# ipro6s register map
Vendor: intelpro; Series: IPRO6S
CPU: ipro6s, little endian
Registers are 32-bit, read-write, reset 0x0 unless marked. A register's access mark holds for its fields unless they carry their own. Offsets are from the block's base; [hi:lo] are bit positions; {n}, {i} and the like mark numbered series.

## RF (part 1 of 2)
Base 0x30001000
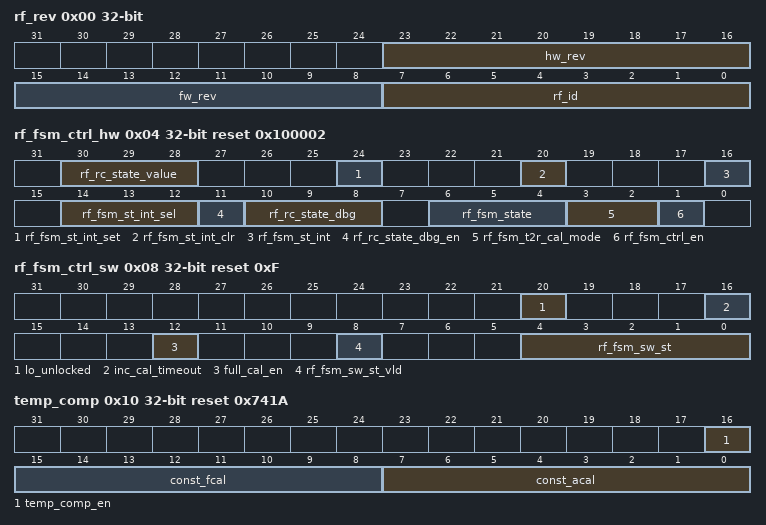
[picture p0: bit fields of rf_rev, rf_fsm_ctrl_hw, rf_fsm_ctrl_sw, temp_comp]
0x00 rf_rev reset not defined — Silicon revision
  [23:16] hw_rev ro — mark digital HW REV ID
  [15:8] fw_rev ro — mark firmware REV ID
  [7:0] rf_id ro — mark RF IP rev ID
0x04 rf_fsm_ctrl_hw reset 0x100002 (reset mask 0x1107F0E) — Digital Control
  [30:28] rf_rc_state_value ro — RC FSM state value
  [24] rf_fsm_st_int_set — RF FSM state interrupt set
  [20] rf_fsm_st_int_clr — RF FSM state interrupt clear
  [16] rf_fsm_st_int ro — RF FSM state interrupt value
  [14:12] rf_fsm_st_int_sel — WiFi FSM ST request, When selection, IRQ for certain ST will be reported 4'h0:FSM comes to RFrdy ST (after RF power up fullcal or power up incremental cal, next ST will be SB) 4'h1:FSM comes to SB ST (should be same as BB FSM status) 4'h2:FSM comes to RX ST (should be same as BB FSM status) 4'h3:FSM comes to TX ST (should be same as BB FSM status) 4'h4:FSM comes to Inccal_ros_afcal (for RF incremental calibration between TX to RX） 4'h5:FSM comes to inccal_tos_afcal (for RF incremental calibration between TX to RX，not RX-to-TX due to limited switching time）
  [11] rf_rc_state_dbg_en — 1:enable RC state from SW
  [10:8] rf_rc_state_dbg — SW RC state value
  [6:4] rf_fsm_state ro — RF FSM state value 0:ST_PD, 1:ST_SB, 2:ST_LO, 3:ST_RX, 4:ST_TX, 5:ST_T2RI, 6:ST_R2T, 7:ST_MS
  [3:2] rf_fsm_t2r_cal_mode — 2'd0:disable incremental calibration between TX/RX/ switching 2'd1:enable incremental ROS/A/F calibration between TX/RX switching 2'd2:(Reserved) enable incremental TOS calibration between TX/RX switching 2'd3:(Reserved) enable incremental ROS/TOS calibration between TX/RX switching
  [1] rf_fsm_ctrl_en — 1:enable HW RF FSM controller
0x08 rf_fsm_ctrl_sw reset 0xF (reset mask 0x1111F) — rfsm status reg
  [20] lo_unlocked ro — LO Unlock signal (hardware connect this signal to SoC interrupts)
  [16] inc_cal_timeout — indicate that inccal has timed out
  [12] full_cal_en — enable full calibration during 1) power up 2) unlocked 3) sw control
  [8] rf_fsm_sw_st_vld — Calibration FSM and function FSM Status Valid Signal, this valid=1 means rf_fsm_st is right available
  [4:0] rf_fsm_sw_st — Calibration FSM and function FSM Status Signal: 0~7: is hardware state; 8~31: is software state
0x0C rfctrl_hw_en — Control logic switch
  [31:0] rf_reserved3
0x10 temp_comp reset 0x741A
  [16] temp_comp_en — 1'b1: enable temperature compensation for LO amplitude and frequency inc_cal
  [15:8] const_fcal — fcal temperature compensaton constant
  [7:0] const_acal — acal temperature compensaton constant
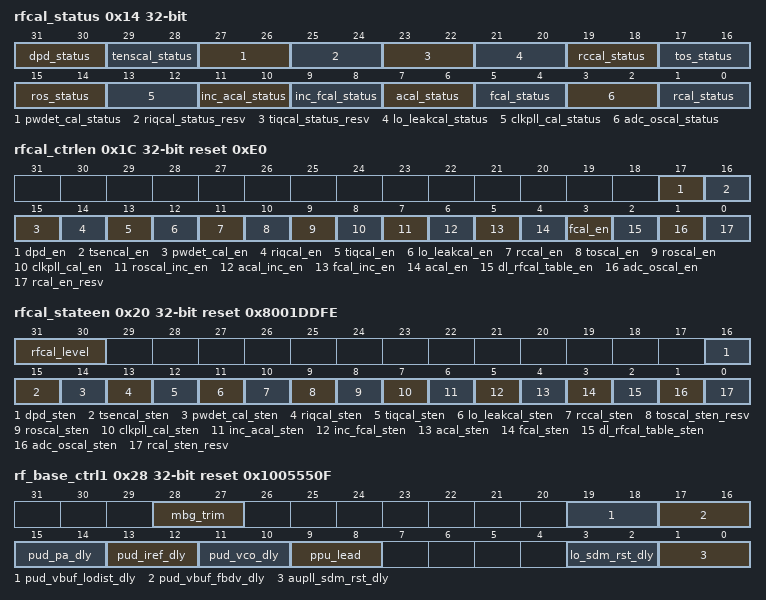
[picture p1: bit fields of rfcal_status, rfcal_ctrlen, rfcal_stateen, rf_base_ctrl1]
0x14 rfcal_status
  [31:30] dpd_status — dpd status : 0: not started, 1: on-going, 2: fail, 3:pass
  [29:28] tenscal_status — tenscal (Tref record) status : 0: not started, 1: on-going, 2: fail, 3:pass
  [27:26] pwdet_cal_status — pwdet_cal status : 0: not started, 1: on-going, 2: fail, 3:pass
  [25:24] riqcal_status_resv — 0: not started, 1: on-going, 2: fail, 3:pass
  [23:22] tiqcal_status_resv — 0: not started, 1: on-going, 2: fail, 3:pass
  [21:20] lo_leakcal_status — 0: not started, 1: on-going, 2: fail, 3:pass
  [19:18] rccal_status — RC calibration status: 0: not started, 1: on-going, 2: fail, 3:pass
  [17:16] tos_status — tos status : 0: not started, 1: on-going, 2: fail, 3:pass
  [15:14] ros_status — ros status : 0: not started, 1: on-going, 2: fail, 3:pass
  [13:12] clkpll_cal_status — clkpll cal status: 0: not started, 1: on-going, 2: fail, 3:pass
  [11:10] inc_acal_status — incremental acal status: 0: not started, 1: on-going, 2: fail, 3:pass
  [9:8] inc_fcal_status — incremental fcal status: 0: not started, 1: on-going, 2: fail, 3:pass
  [7:6] acal_status — acal status: 0: not started, 1: on-going, 2: fail, 3:pass
  [5:4] fcal_status — fcal status: 0: not started, 1: on-going, 2: fail, 3:pass
  [3:2] adc_oscal_status — GPADC and SARADC os cal status: 0: not started, 1: on-going, 2: fail, 3:pass
  [1:0] rcal_status — rcal status : 0: not started, 1: on-going, 2: fail, 3:pass
0x18 rfcal_status2
  [1:0] dl_rfcal_table_status — no calibration, just download RFCAL table status : 0: not started, 1: on-going, 2: fail, 3:pass
0x1C rfcal_ctrlen reset 0xE0 — Calibration mode register
  [17] dpd_en — 1'b1: enable dpd mode
  [16] tsencal_en — reserved
  [15] pwdet_cal_en — 1'b1: enable power det calibration
  [14] riqcal_en — BB IP has RX IQ already
  [13] tiqcal_en — 1'b1: enable calibration
  [12] lo_leakcal_en — 1'b1: enable calibration
  [11] rccal_en — 1'b1: enable RCCAL
  [10] toscal_en — 1'b1: enable TOSCAL
  [9] roscal_en — 1'b1: enable ROSCAL
  [8] clkpll_cal_en — 1'b1: enable clkpll cal
  [7] roscal_inc_en — 1'b1: enable increamental roscal
  [6] acal_inc_en — 1'b1: enable increamental ACAL
  [5] fcal_inc_en — 1'b1: enable increamental FCAL
  [4] acal_en — 1'b1: enable ACAL
  [3] fcal_en — 1’b1:enable FCAL when pu_cal_fcal=1
  [2] dl_rfcal_table_en — 1'b1: enable download RFCAL table, no calibrations
  [1] adc_oscal_en — 1'b1: enable GPADC and SARADC OS calibration
  [0] rcal_en_resv — no RCAL in this version
0x20 rfcal_stateen reset 0x8001DDFE — rf calibration state enabl in full cal list
  [31:30] rfcal_level — rf calbiration level: 1:fast calibration, download previous table; 2: full cal without ATE onetime cal; 3: full cal with ATE onetime cal; during ATE, change the value from 2 to 3;
  [16] dpd_sten — 1'b1: enable dpd state in calibration list
  [15] tsencal_sten — 1'b1: enable temperature sensor calibration state in calibration list
  [14] pwdet_cal_sten — 1'b1: enable power det calibration state in calibration list
  [13] riqcal_sten — Because CEVA IP has RX IQ already, reserved
  [12] tiqcal_sten — 1'b1: enable calibration state in calibration list
  [11] lo_leakcal_sten — 1'b1: enable calibration state in calibration list
  [10] rccal_sten — 1'b1: enable RCCAL state in calibration list
  [9] toscal_sten_resv — 1'b1: enable tOSCAL state in calibration list
  [8] roscal_sten — 1'b1: enable ROSCAL state in calibration list
  [7] clkpll_cal_sten — 1'b1: enable clkpll calibration state in calibration list
  [6] inc_acal_sten — 1'b1: enable increamental ACAL state in calibration list
  [5] inc_fcal_sten — 1'b1: enable increamental FCAL state in calibration list
  [4] acal_sten — 1'b1: enable ACAL state in calibration list
  [3] fcal_sten — 1’b1:enable FCAL state in calibration list
  [2] dl_rfcal_table_sten — 1'b1: enable download RFCAL table state, no other calibrations
  [1] adc_oscal_sten — 1'b1: enable GPADC and SARADC OS calibration
  [0] rcal_sten_resv — 1'b1: enable RCAL state in calibration list
0x24 saradc_resv reset not defined — SARADC Control Registers
0x28 rf_base_ctrl1 reset 0x1005550F — ZRF Control register 0
  [28:27] mbg_trim — (added)bandgap curve trimming
  [19:18] pud_vbuf_lodist_dly — PUD_VBUF_LODIST delay, PUD delay to bypass resistor to charge the capacitor fast 2'b00: 2 us 2'b01: 4 us 2'b10: 6 us 2'b11: 8 us
  [17:16] pud_vbuf_fbdv_dly — PUD_VBUF_FBDV delay, PUD delay to bypass resistor to charge the capacitor fast 2'b00: 2 us 2'b01: 4 us 2'b10: 6 us 2'b11: 8 us
  [15:14] pud_pa_dly — PUD_PA delay, to bypass R in RC filtering for fast settling at REF_CLK rate 2'b00: 1.5 us 2'b01: 3 us 2'b10: 4.5 us 2'b11: 6 us
  [13:12] pud_iref_dly — PUD_IREF delay, to bypass R in RC filtering for fast settling at REF_CLK rate 2'b00: 2 us 2'b01: 4 us 2'b10: 6 us 2'b11: 8 us
  [11:10] pud_vco_dly — PUD_VCO delay, PUD delay to bypass resistor to charge the capacitor fast 2'b00: 2 us 2'b01: 4 us 2'b10: 6 us 2'b11: 8 us
  [9:8] ppu_lead — pre PD signal lead to PU signal, to define lead time between PPU_xxxx and PU_xxx, ex: PPU_VCO and PU_VCO 2'b00: 0.2 us 2'b01: 0.4 us 2'b10: 0.6 us 2'b11: 0.8 us
  [3:2] lo_sdm_rst_dly — programable ref_clk delay, from falling edge of ana_sdm_rst to falling edge of ctrl_txdp_clr
  [1:0] aupll_sdm_rst_dly — programable ref_clk delay, from falling edge of ana_sdm_rst to falling edge of ctrl_txdp_clr
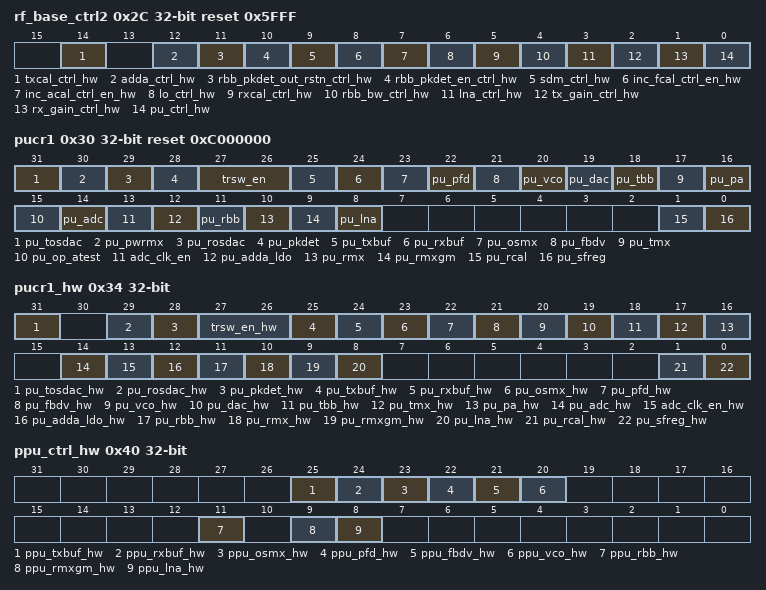
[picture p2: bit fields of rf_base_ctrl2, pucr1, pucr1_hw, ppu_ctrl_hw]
0x2C rf_base_ctrl2 reset 0x5FFF — ZRF Control register 0
  [14] txcal_ctrl_hw — 1: tx calibration related control bits are controlled by dsp 0: tx calibration related control bits are controlled by this register map Related Signals: tbb_tosdac_i/tbb_tosdac_q/tx_iqc_gain/tx_iqc_phase
  [12] adda_ctrl_hw — 1: adda_lo_dvddsel is controlled by dsp 0: adda_lo_dvddse is controlled by this register map
  [11] rbb_pkdet_out_rstn_ctrl_hw — 1: rbb_pkdet_out_rstn is controlled by dsp 0: rbb_pkdet_out_rstn is controlled by this register map
  [10] rbb_pkdet_en_ctrl_hw — 1: rbb_pkdet_en is controlled by dsp 0: rbb_pkdet_en is controlled by this register map
  [9] sdm_ctrl_hw — 1: lo sdm dither related control bits are controlled by dsp 0: lo sdm dither related control bits are controlled by this register map Related Signals: lo_sdm_bypass
  [8] inc_fcal_ctrl_en_hw — 1: fcal_inc_en is controlled by dsp 0: fcal_inc_en are controlled by this register map
  [7] inc_acal_ctrl_en_hw — 1: acal_inc_en is controlled by dsp 0: acal_inc_en is controlled by this register map
  [6] lo_ctrl_hw — 1: lo bandwidth/idac/fcw control bits are controlled by hardware logic input 0: lo bandwidth/idac/fcw control bits are controlled by this register map Related Singals: fsm_lo_sdm, fsm_lo_sdm_rstb, fsm_lo_fbdv_rst, fsm_lo_pfd_rst_csd, lo_fbdv_halfstep_en, lo_cp_sel, lo_lf_cz, lo_lf_rz, lo_lf_r4
  [5] rxcal_ctrl_hw — 1: rx calibration related control bits are controlled by dsp 0: rx calibration related control bits are controlled by this register map value Related Signals: rosdac_i_hw/rosdac_q_hw
  [4] rbb_bw_ctrl_hw — 1: rbb_bt_mode is controlled by dsp 0: rbb_bt_mode is controlled by this register map value
  [3] lna_ctrl_hw — 1: lna bm and csw are controlled by hardware logic input 0: lna bm and csw are controlled by this register map
  [2] tx_gain_ctrl_hw — 1: TX gain control are controlled by hardware logic input, ex gx_xxx_hw 0: TX gain control bits are controlled by this register map gc_xxx value
  [1] rx_gain_ctrl_hw — 1: RX gain control are controlled by hardware logic input, ex gx_xxx_hw 0: RX gain control bits are controlled by this register map gc_xxx value
  [0] pu_ctrl_hw — 1: pu control bits are controlled by hardware logic input, ex: pu_xxx_hw 0: pu regs are controlled by this register map pu_xxx value
0x30 pucr1 reset 0xC000000
  [31] pu_tosdac — 1'b1: power up TOSDAC
  [30] pu_pwrmx — 1'b1: power up power mx
  [29] pu_rosdac — 1'b1: power up TIA ROSDAC
  [28] pu_pkdet — 1'b1: power up TIA PKDET
  [27:26] trsw_en — 2'b3: TX mode 2'b0: RX mode
  [25] pu_txbuf — 1'b1: power up TX BUF
  [24] pu_rxbuf — 1'b1: power up RX BUF
  [23] pu_osmx — 1'b1: power up OSMX
  [22] pu_pfd — 1'b1: power up Charge Pump/PFD
  [21] pu_fbdv — 1'b1: power up FBDV
  [20] pu_vco — 1'b1: power up DCO
  [19] pu_dac — 1'b1: power up DAC
  [18] pu_tbb — 1'b1: power up TBB
  [17] pu_tmx — 1'b1: power up TMX
  [16] pu_pa — 1'b1: power up PA
  [15] pu_op_atest — 1'b1: power up atest buffer
  [14] pu_adc — 1'b1: power up ADC
  [13] adc_clk_en — 1'b1: Clock enable
  [12] pu_adda_ldo — 1'b1: power up ADDA LDO
  [11] pu_rbb — 1'b1: power up RBB
  [10] pu_rmx — 1'b1: power up RMX
  [9] pu_rmxgm — 1'b1: power up RMXGM
  [8] pu_lna — 1'b1: power up LNA
  [1] pu_rcal — 1'b1: power up rcal block
  [0] pu_sfreg — 1'b1: power up source follow regular
0x34 pucr1_hw reset not defined — read only from hardware logic
  [31] pu_tosdac_hw ro — 1'b1: power up TOSDAC
  [29] pu_rosdac_hw ro — 1'b1: power up TIA ROSDAC
  [28] pu_pkdet_hw ro — 1'b1: power up TIA PKDET
  [27:26] trsw_en_hw ro — 2'b3: TX mode 2'b0: RX mode
  [25] pu_txbuf_hw ro — 1'b1: power up TX BUF
  [24] pu_rxbuf_hw ro — 1'b1: power up RX BUF
  [23] pu_osmx_hw ro — 1'b1: power up OSMX
  [22] pu_pfd_hw ro — 1'b1: power up Charge Pump/PFD
  [21] pu_fbdv_hw ro — 1'b1: power up FBDV
  [20] pu_vco_hw ro — 1'b1: power up DCO
  [19] pu_dac_hw ro — 1'b1: power up DAC
  [18] pu_tbb_hw ro — 1'b1: power up TBB
  [17] pu_tmx_hw ro — 1'b1: power up TMX
  [16] pu_pa_hw ro — 1'b1: power up PA
  [14] pu_adc_hw ro — 1'b1: power up ADC
  [13] adc_clk_en_hw ro — 1'b1: Clock enable
  [12] pu_adda_ldo_hw ro — 1'b1: power up ADDA LDO
  [11] pu_rbb_hw ro — 1'b1: power up RBB
  [10] pu_rmx_hw ro — 1'b1: power up RMX
  [9] pu_rmxgm_hw ro — 1'b1: power up RMXGM
  [8] pu_lna_hw ro — 1'b1: power up LNA
  [1] pu_rcal_hw ro — 1'b1: power up rcal block
  [0] pu_sfreg_hw ro — 1'b1: power up source follow regular
0x38 pucr2 reset not defined
0x3C pucr2_hw reset not defined
0x40 ppu_ctrl_hw reset not defined
  [25] ppu_txbuf_hw ro — ppu_lead time ahead of pu_txbuf or pu_txbuf_hw
  [24] ppu_rxbuf_hw ro — ppu_lead time ahead of pu_rxbuf or pu_rxbuf_hw
  [23] ppu_osmx_hw ro — ppu_lead time ahead of pu_osmx or pu_osmx_hw
  [22] ppu_pfd_hw ro — ppu_lead time ahead of pu_pfd or pu_pfd_hw
  [21] ppu_fbdv_hw ro — ppu_lead time ahead of pu_fbdv or pu_fbdv_hw
  [20] ppu_vco_hw ro — ppu_lead time ahead of pu_vco or pu_vco_hw
  [11] ppu_rbb_hw ro — pu_rbb_hw
  [9] ppu_rmxgm_hw ro — ppu_lead time ahead of pu_rmxgm or pu_rmxgm_hw
  [8] ppu_lna_hw ro — pu_lna_hw
0x44 pud_ctrl_hw reset not defined
  [20] pud_vco_hw ro — pud_vco_dly time after of pu_vco or pu_vco_hw
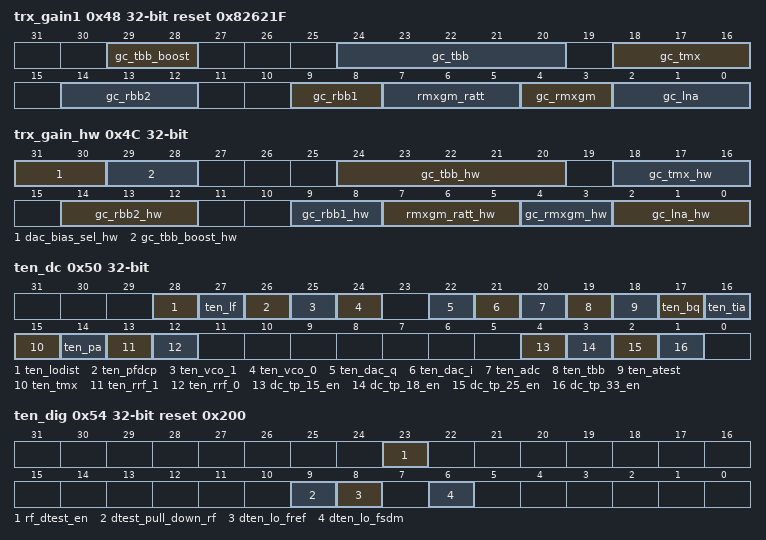
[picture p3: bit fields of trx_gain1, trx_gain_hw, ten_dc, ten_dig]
0x48 trx_gain1 reset 0x82621F — gain control1
  [29:28] gc_tbb_boost — 0: 0x, 1: 4x, 2: 4x, 3: 8x
  [24:20] gc_tbb — 0: 0.5x, 1: 2x … 15: 8x … 31: 16x
  [18:16] gc_tmx — tmx gain code
  [14:12] gc_rbb2 — rbb_gain2: 3'b000:-6dB, 3'b001:-4dB, 3'b010:-2dB, 3'b011:0dB, 3'b100:2dB, 3'b101:4dB, 3'b110:6dB, 3'b111:8dB
  [9:8] gc_rbb1 — rbb_gain1:1'b00:-6dB, 1'b01:0dB, 1'b10:6dB, 1'b11:rsvd
  [7:5] rmxgm_ratt — 0: 0dB, 1:-6dB, 2:-9dB, 3:-12dB
  [4:3] gc_rmxgm — rmxgm_gc: 2'h3:highest gain, 2'h1:highest gain -6dB, and 10M mode highest gain, 2'h0: -12dB
  [2:0] gc_lna — lna_gain: 3'b7:57dB, 3'b6:51dB, 3'b5:45dB, 3'b4:39dB, 3'b3:33dB, 3'b2:27dB, 3'b1:21dB, 3'b0:15dB
0x4C trx_gain_hw reset not defined — trx gain hardware readback
  [31:30] dac_bias_sel_hw ro — dac_bias_sel readback
  [29:28] gc_tbb_boost_hw ro — gc_tbb_boost readback
  [24:20] gc_tbb_hw ro — gc_tbb readback
  [18:16] gc_tmx_hw ro — gc_tmx readback
  [14:12] gc_rbb2_hw ro — gc_rbb2 readback
  [9:8] gc_rbb1_hw ro — gc_rbb1 readback
  [7:5] rmxgm_ratt_hw ro — rmgm_ratt_readback
  [4:3] gc_rmxgm_hw ro — gc_rmxgm readback
  [2:0] gc_lna_hw ro — gc_lna readback
0x50 ten_dc — dc test register
  [28] ten_lodist — 1'b1: enable this block dc test
  [27] ten_lf — 1'b1: enable this block dc test
  [26] ten_pfdcp — 1'b1: enable this block dc test
  [25] ten_vco_1 — 1'b1: enable this block dc test
  [24] ten_vco_0 — 1'b1: enable this block dc test
  [22] ten_dac_q — 1'b1: enable this block dc test
  [21] ten_dac_i — 1'b1: enable this block dc test
  [20] ten_adc — 1'b1: enable this block dc test
  [19] ten_tbb — 1'b1: enable this block dc test
  [18] ten_atest — 1'b1: enable this block dc test
  [17] ten_bq — 1'b1: enable this block dc test
  [16] ten_tia — 1'b1: enable this block dc test
  [15] ten_tmx — 1'b1: enable this block dc test
  [14] ten_pa — 1'b1: enable this block dc test
  [13] ten_rrf_1 — 1'b1: enable this block dc test
  [12] ten_rrf_0 — 1'b1: enable this block dc test
  [4] dc_tp_15_en — 1'b1: enable dc_15 test
  [3] dc_tp_18_en — 1'b1: enable dc_18 test
  [2] dc_tp_25_en — 1'b1: enable dc_25 test
  [1] dc_tp_33_en — 1'b1: enable dc_33 test
0x54 ten_dig reset 0x200 — digital test register
  [23] rf_dtest_en — 1: enable RF digital test to pad switch
  [9] dtest_pull_down_rf — 1'b1: enable this blcok dtest
  [8] dten_lo_fref — 1'b1: enable this blcok dtest
  [6] dten_lo_fsdm — 1'b1: enable this blcok dtest
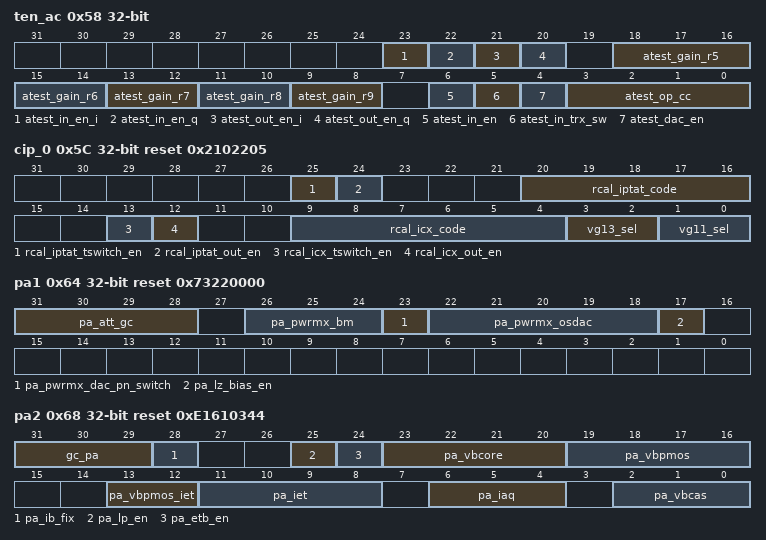
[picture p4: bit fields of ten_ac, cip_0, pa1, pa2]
0x58 ten_ac — ac test register
  [23] atest_in_en_i — 1'b1: enable atest input switch for I channel
  [22] atest_in_en_q — 1'b1: enable atest input switch for Q channel
  [21] atest_out_en_i — 1'b1: enable atest output switch for I channel
  [20] atest_out_en_q — 1'b1: enable atest output switch for Q channel
  [18:16] atest_gain_r5
  [27-2n:26-2n] atest_gain_r{n} (n=6..9)
  [6] atest_in_en
  [5] atest_in_trx_sw
  [4] atest_dac_en
  [3:0] atest_op_cc
0x5C cip_0 reset 0x2102205 — RX normal bias mode registers
  [25] rcal_iptat_tswitch_en
  [24] rcal_iptat_out_en
  [20:16] rcal_iptat_code
  [13] rcal_icx_tswitch_en
  [12] rcal_icx_out_en
  [9:4] rcal_icx_code
  [3:2] vg13_sel — 0: 1.25V, 1: 1.3V, 2: 1.35V, 3: 1.4V
  [1:0] vg11_sel — vg13-vg11 delta voltage. 0: 0.15V, 1: 0.2V, 2: 0.25V, 3: 0.3V
0x60 pa0 reset 0x1
  [1:0] pa_pwrmx_osdac_bm
0x64 pa1 reset 0x73220000
  [31:28] pa_att_gc — pa output atentuator gain code
  [26:24] pa_pwrmx_bm — pa power mixer bias mode
  [23] pa_pwrmx_dac_pn_switch — pa power mixer offset dac output p/n switch
  [22:18] pa_pwrmx_osdac — pa power mixer offset dac code
  [17] pa_lz_bias_en
0x68 pa2 reset 0xE1610344 — RX normal bias mode registers
  [31:29] gc_pa, [28] pa_ib_fix, [25] pa_lp_en, [24] pa_etb_en, [23:20] pa_vbcore, [19:16] pa_vbpmos, [13:12] pa_vbpmos_iet, [11:8] pa_iet, [6:4] pa_iaq, [2:0] pa_vbcas
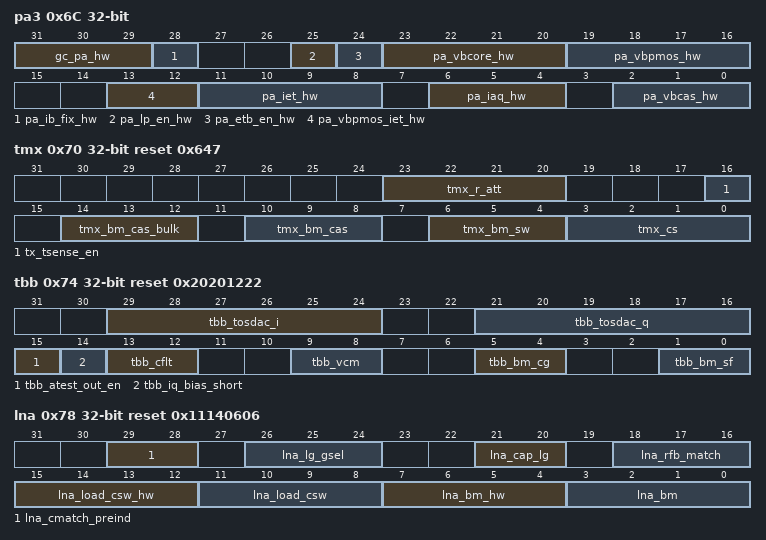
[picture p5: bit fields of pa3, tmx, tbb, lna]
0x6C pa3 reset not defined
  [31:29] gc_pa_hw ro, [28] pa_ib_fix_hw ro, [25] pa_lp_en_hw ro, [24] pa_etb_en_hw ro, [23:20] pa_vbcore_hw ro, [19:16] pa_vbpmos_hw ro, [13:12] pa_vbpmos_iet_hw ro, [11:8] pa_iet_hw ro, [6:4] pa_iaq_hw ro, [2:0] pa_vbcas_hw ro
0x70 tmx reset 0x647
  [23:20] tmx_r_att
  [16] tx_tsense_en — tx temperature sensor enable
  [14:12] tmx_bm_cas_bulk
  [10:8] tmx_bm_cas
  [6:4] tmx_bm_sw
  [3:0] tmx_cs — tmx xfmr output stage cap tuning contrl
0x74 tbb reset 0x20201222
  [29:24] tbb_tosdac_i
  [21:16] tbb_tosdac_q
  [15] tbb_atest_out_en
  [14] tbb_iq_bias_short
  [13:12] tbb_cflt
  [9:8] tbb_vcm — 0: 500mV, 1: 550mV, 2: 600mV, 3: 650mV
  [5:4] tbb_bm_cg — 0: 0.1mA, 1: 0.15mA, 2: 0.2mA, 3: 0.25mA
  [1:0] tbb_bm_sf — 0: 0.2mA, 1: 0.3mA, 3: 0.4mA, 4: 0.5mA
0x78 lna reset 0x11140606 (reset mask 0x37370F0F)
  [29:28] lna_cmatch_preind
  [26:24] lna_lg_gsel — lna LG gain control by tuning current mirror size
  [21:20] lna_cap_lg — lna LG input tuning cap control
  [18:16] lna_rfb_match — lna input feedback resistor control
  [15:12] lna_load_csw_hw ro — lna_load_csw hardware read back
  [11:8] lna_load_csw — lna loading cap tuning control
  [7:4] lna_bm_hw ro — lna_bm hardware read back
  [3:0] lna_bm — lna bias current control, default: hg=6, lg=4
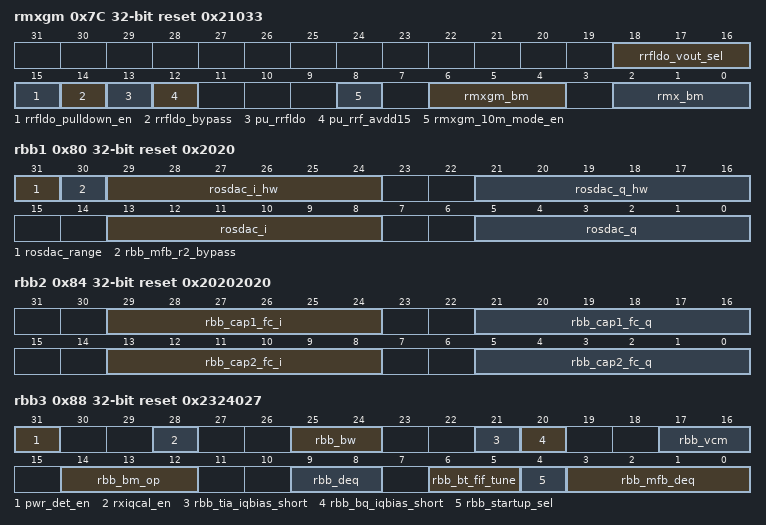
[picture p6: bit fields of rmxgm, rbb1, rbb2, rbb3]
0x7C rmxgm reset 0x21033
  [18:16] rrfldo_vout_sel — 0:1.62V, 1:1.72V, 2:1.82V, 3:1.92V, 4:2.02V
  [15] rrfldo_pulldown_en — 1'h1: enable rrfldo pulldown
  [14] rrfldo_bypass — 1'h1: bypass mode
  [13] pu_rrfldo — 1'h1: rrfldo pu ctrl by pu_adda_ldo from fsm, 1'h0: rrfldo always off
  [12] pu_rrf_avdd15 — 1'h1: LNA use supply from ldo15rf
  [8] rmxgm_10m_mode_en — 1'h0: wifi mode, 1'h1: 10m mode
  [6:4] rmxgm_bm — rmxgm bias current control, default = 3
  [2:0] rmx_bm — rmx bias voltage control, default = 3 , 0.85V
0x80 rbb1 reset 0x2020 (reset mask 0xC0003F3F)
  [31] rosdac_range
  [30] rbb_mfb_r2_bypass — 0: 4th order LPF, 1: 3rd order LPF
  [29:24] rosdac_i_hw ro
  [21:16] rosdac_q_hw ro
  [13:8] rosdac_i
  [5:0] rosdac_q
0x84 rbb2 reset 0x20202020
  [29:24] rbb_cap1_fc_i — capbank tuning for TIA I channel
  [21:16] rbb_cap1_fc_q — capbank tuning for TIA Q channel
  [13:8] rbb_cap2_fc_i — capbank tuning for BQ I channel
  [5:0] rbb_cap2_fc_q — capbank tuning for BQ Q channel
0x88 rbb3 reset 0x2324027
  [31] pwr_det_en — power detect related signal path enable control
  [28] rxiqcal_en — rxiqcal related signal path enable control
  [25:24] rbb_bw — 0: n/a, 1: 5M mode, 2:10M mode, 3: 20M mode
  [21] rbb_tia_iqbias_short
  [20] rbb_bq_iqbias_short
  [17:16] rbb_vcm — 0: 610mV, 1: 650mV, 2: 690mV, 3:720mV
  [14:12] rbb_bm_op — 0: 50%, 1: 62.5%, 2: 75%, 3: 87.5%, 4: 100%, 5: 112.5%, 6: 125%, 7: 137.5%
  [9:8] rbb_deq
  [6:5] rbb_bt_fif_tune
  [4] rbb_startup_sel — 0: track corner, 1: track vcm
  [3:0] rbb_mfb_deq — 7: r2_mfb=200Ohm
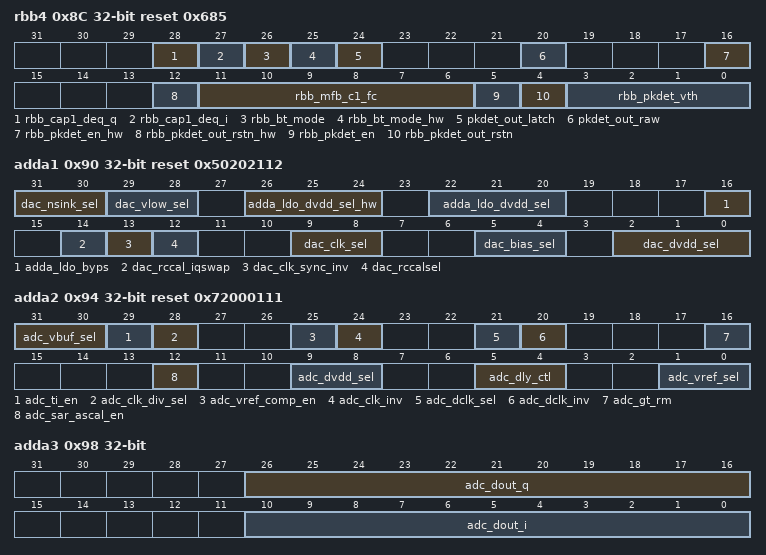
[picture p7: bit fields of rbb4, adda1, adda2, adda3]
0x8C rbb4 reset 0x685 (reset mask 0x1C000FFF)
  [28] rbb_cap1_deq_q
  [27] rbb_cap1_deq_i
  [26] rbb_bt_mode
  [25] rbb_bt_mode_hw ro — controlled by rbb_bw_ctrl_hw
  [24] pkdet_out_latch ro
  [20] pkdet_out_raw ro
  [16] rbb_pkdet_en_hw ro
  [12] rbb_pkdet_out_rstn_hw ro
  [11:6] rbb_mfb_c1_fc — 0x1a:C1_mfb=10pF
  [5] rbb_pkdet_en
  [4] rbb_pkdet_out_rstn
  [3:0] rbb_pkdet_vth
0x90 adda1 reset 0x50202112 (reset mask 0xF0717337)
  [31:30] dac_nsink_sel — 2'b00: 0 bias offset 2'b01: 10uA bias offset 2'b10: 20uA bias offset 2'b11: 30uA bias offset
  [29:28] dac_vlow_sel
  [26:24] adda_ldo_dvdd_sel_hw ro
  [22:20] adda_ldo_dvdd_sel — 3'h0: dvdd20=1.80V 3'h1: dvdd20=1.90V 3'h2: dvdd20=2.0V (default for ADC) 3'h3: dvdd20=2.05V 3'h4: dvdd20=2.1V (default for DAC) 3'h5: dvdd20=2.15V 3'h6: dvdd20=2.2V 3'h7: dvdd20=2.25V
  [16] adda_ldo_byps — 1'b0: ldo not bypass 1'b1: ldo bypass
  [14] dac_rccal_iqswap — 1'b0: Normal 1'b1: rccal output IQ swap
  [13] dac_clk_sync_inv — 1'b0: clock falling edge to sync input data 1'b1: clock rising edge to sync input data
  [12] dac_rccalsel — 1'b0: Normal 1'b1: output to dodpin
  [9:8] dac_clk_sel — 2'b00: 80 clock duty cycle for power up fast settling 2'b01: 160 clock duty cycle for power up fast settling 2'b10: 320 clock duty cycle for power up fast settling 2'b11: 640 clock duty cycle for power up fast settling
  [5:4] dac_bias_sel — 2'b00: LSB=0.375uA 2'b01: LSB=0.5uA 2'b10: LSB=0.625uA 2'b11: LSB=0.75uA
  [2:0] dac_dvdd_sel — 3'h1: dvdd11=1.15V 3'h2: dvdd11=1.20V 3'h3: dvdd11=1.25V 3'h4: dvdd11=1.3V 3'h5: dvdd11=1.35V 3'h6: dvdd11=1.4V 3'h7: dvdd11=1.45V
0x94 adda2 reset 0x72000111
  [31:30] adc_vbuf_sel — 2'h0:vbuf_out current= 100uA 2'h1:vbuf_out current= 150uA 2'h2:vbuf_out current= 200uA 2'h3:vbuf_out current= 250uA
  [29] adc_ti_en — 1'b0: disable Time Interleave 1'b1: enable Time Interleave
  [28] adc_clk_div_sel — 1'b0: 80MHz 1'b1: 160MHz
  [25] adc_vref_comp_en — 1'b1: Enable Vref Reference Charge Neutralization
  [24] adc_clk_inv — 1'b0: non_invert 1'b1: Invert
  [21] adc_dclk_sel — 1'b0: I channel 1'b1: Q channel
  [20] adc_dclk_inv — 1'b0: falling edge synchronize data 1'b1: rising edge synchronize data
  [16] adc_gt_rm — 1'b0: glitch remove disable 1'b1: glitch remove enable
  [12] adc_sar_ascal_en — 1'b0: adc offset cal disable 1'b1:adc offset cal enable
  [9:8] adc_dvdd_sel — 2'b00: dvdd11=1V 2'b01: dvdd11=1.1V 2'b10: dvdd11=1.2V 2'b11: dvdd11=1.3V
  [5:4] adc_dly_ctl — 2'b00:~2'b11: getting faster
  [1:0] adc_vref_sel — 2'b00: VREF=1V 2'b01: VREF=1.05V 2'b10: VREF=1.1V 2'b11: VREF=1.15V
0x98 adda3 reset not defined
  [26:16] adc_dout_q ro, [10:0] adc_dout_i ro
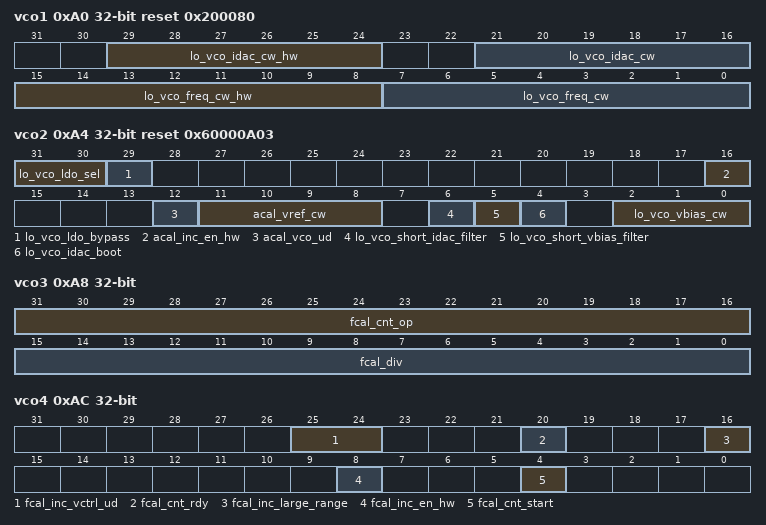
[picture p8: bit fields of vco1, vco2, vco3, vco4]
0xA0 vco1 reset 0x200080 (reset mask 0x3F00FF)
  [29:24] lo_vco_idac_cw_hw ro — current source code of vco
  [21:16] lo_vco_idac_cw — current source code of vco
  [15:8] lo_vco_freq_cw_hw ro — vco core capbank control word
  [7:0] lo_vco_freq_cw — vco core capbank control word
0xA4 vco2 reset 0x60000A03 (reset mask 0xE0000F77)
  [31:30] lo_vco_ldo_sel
  [29] lo_vco_ldo_bypass
  [16] acal_inc_en_hw ro
  [12] acal_vco_ud ro
  [11:8] acal_vref_cw — default: 626mV, step 20mV/code
  [6] lo_vco_short_idac_filter — short idac gate resistor
  [5] lo_vco_short_vbias_filter — short varactor bias rc filter resistor
  [4] lo_vco_idac_boot — extra current for vco core
  [2:0] lo_vco_vbias_cw — varactor and capbank bias voltage control word
0xA8 vco3 (reset mask 0xFFFF)
  [31:16] fcal_cnt_op ro, [15:0] fcal_div
0xAC vco4 (reset mask 0x10010)
  [25:24] fcal_inc_vctrl_ud ro, [20] fcal_cnt_rdy ro, [16] fcal_inc_large_range, [8] fcal_inc_en_hw ro, [4] fcal_cnt_start
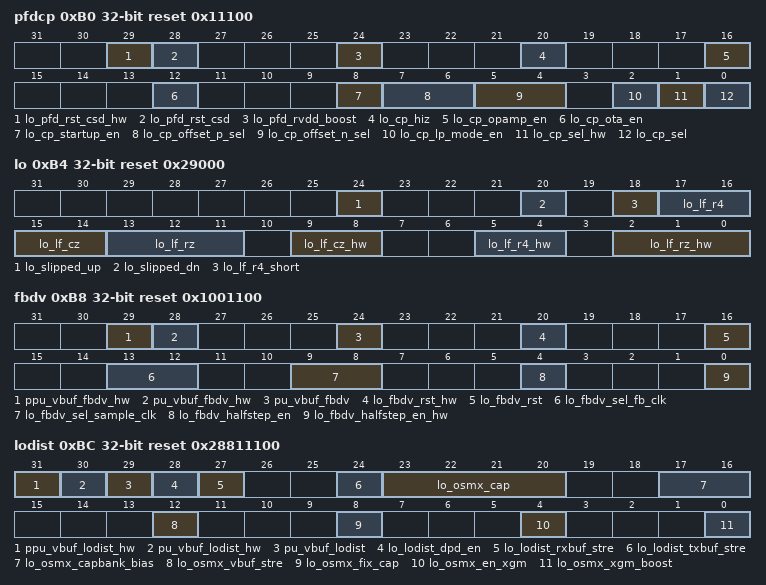
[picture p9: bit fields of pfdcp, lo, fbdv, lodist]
0xB0 pfdcp reset 0x11100 (reset mask 0x111111F5)
  [29] lo_pfd_rst_csd_hw ro — clear csd output
  [28] lo_pfd_rst_csd — clear csd output
  [24] lo_pfd_rvdd_boost — boost the rvdd voltage of the PFDCP
  [20] lo_cp_hiz — 1'h1 enable the high z state
  [16] lo_cp_opamp_en — 1'h1 enable the super source follower opamp
  [12] lo_cp_ota_en — 1'h1 enable the improve current mirror output resistance purpose OTA
  [8] lo_cp_startup_en — 1'h1 enable the startup circuit
  [7:6] lo_cp_offset_p_sel
  [5:4] lo_cp_offset_n_sel
  [2] lo_cp_lp_mode_en
  [1] lo_cp_sel_hw ro — lo_cp_sel hardware read back
  [0] lo_cp_sel — 1'h0: 160uA, 1'h1: 240uA
0xB4 lo reset 0x29000 (reset mask 0x7F800)
  [24] lo_slipped_up ro
  [20] lo_slipped_dn ro
  [18] lo_lf_r4_short
  [17:16] lo_lf_r4 — 0:6.1k, 1:9.1k, 2:12.2k, 3:15.2k, 4:18.2k, 5:21.2k, 6:24.2k, 7:24.2k
  [15:14] lo_lf_cz — 0:240pF, 1:280pF, 2:320pF, 3:360pF
  [13:11] lo_lf_rz — 0:6.11k, 1:9.13k, 2:12.16k, 3:15.18k, 4:18.21k, 5:21.23k, 6:24.24k, 6:24.24k
  [9:8] lo_lf_cz_hw ro
  [5:4] lo_lf_r4_hw ro
  [2:0] lo_lf_rz_hw ro
0xB8 fbdv reset 0x1001100 (reset mask 0x1013310)
  [29] ppu_vbuf_fbdv_hw ro
  [28] pu_vbuf_fbdv_hw ro
  [24] pu_vbuf_fbdv
  [20] lo_fbdv_rst_hw ro
  [16] lo_fbdv_rst
  [13:12] lo_fbdv_sel_fb_clk — notes: 00->mod1, 01->mod2, 1x->mod3
  [9:8] lo_fbdv_sel_sample_clk — notes: 00->mod4(32 to 127), 01->mod5(64 to 255), 1x->mod6(128 to 511)
  [4] lo_fbdv_halfstep_en — enable halfstep fbdiv
  [0] lo_fbdv_halfstep_en_hw ro
0xBC lodist reset 0x28811100 (reset mask 0x39F31111)
  [31] ppu_vbuf_lodist_hw ro, [30] pu_vbuf_lodist_hw ro, [29] pu_vbuf_lodist, [28] lo_lodist_dpd_en, [27] lo_lodist_rxbuf_stre, [24] lo_lodist_txbuf_stre, [23:20] lo_osmx_cap, [17:16] lo_osmx_capbank_bias, [12] lo_osmx_vbuf_stre, [8] lo_osmx_fix_cap, [4] lo_osmx_en_xgm, [0] lo_osmx_xgm_boost
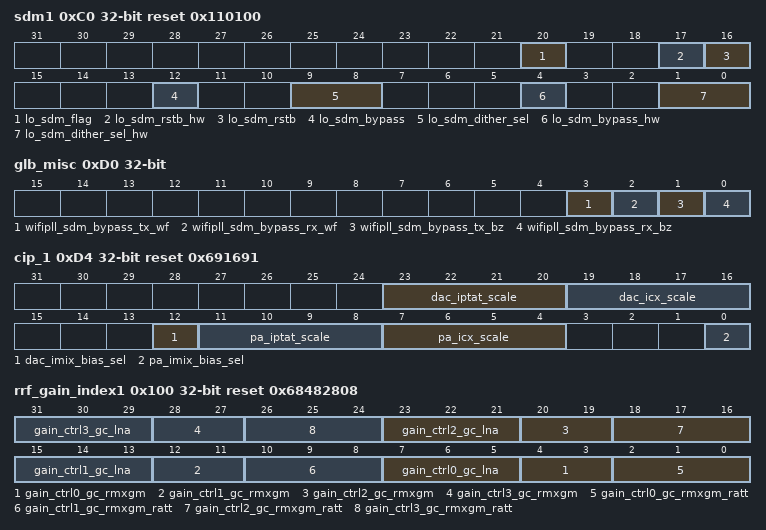
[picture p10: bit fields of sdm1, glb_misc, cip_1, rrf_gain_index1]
0xC0 sdm1 reset 0x110100 (reset mask 0x111300)
  [20] lo_sdm_flag — flag=0 -> sdmout all 1
  [17] lo_sdm_rstb_hw ro — resetb for sdm
  [16] lo_sdm_rstb — resetb for sdm
  [12] lo_sdm_bypass — bypass=1, sdmout=sdmin[29:22]
  [9:8] lo_sdm_dither_sel — select dither option for sdm
  [4] lo_sdm_bypass_hw ro
  [1:0] lo_sdm_dither_sel_hw ro
0xC4 sdm2 reset 0x1501C71C
  [29:0] lo_sdmin — sdm input, U(30,22)
0xC8 sdm3 reset not defined
  [29:0] lo_sdmin_hw ro
0xCC refbuf reset 0x200000
  [21] lo_refbuf_loclk_en
0xD0 glb_misc
  [3] wifipll_sdm_bypass_tx_wf, [2] wifipll_sdm_bypass_rx_wf, [1] wifipll_sdm_bypass_tx_bz, [0] wifipll_sdm_bypass_rx_bz
0xD4 cip_1 reset 0x691691 — RX normal bias mode registers
  [23:20] dac_iptat_scale, [19:16] dac_icx_scale, [12] dac_imix_bias_sel, [11:8] pa_iptat_scale, [7:4] pa_icx_scale, [0] pa_imix_bias_sel
0xEC rf_resv_reg_0 reset 0xFFFF0000
  [31:0] rf_reserved0
0xF0 rf_resv_reg_1
  [31:0] rf_reserved1
0xF4 rf_resv_reg_2 reset not defined
  [31:0] rf_reserved2 ro
0x100 rrf_gain_index1 reset 0x68482808
  [8n+7:8n+5] gain_ctrl{n}_gc_lna (n=0..3), [8n+4:8n+3] gain_ctrl{n}_gc_rmxgm (n=0..3), [8n+2:8n] gain_ctrl{n}_gc_rmxgm_ratt (n=0..3)
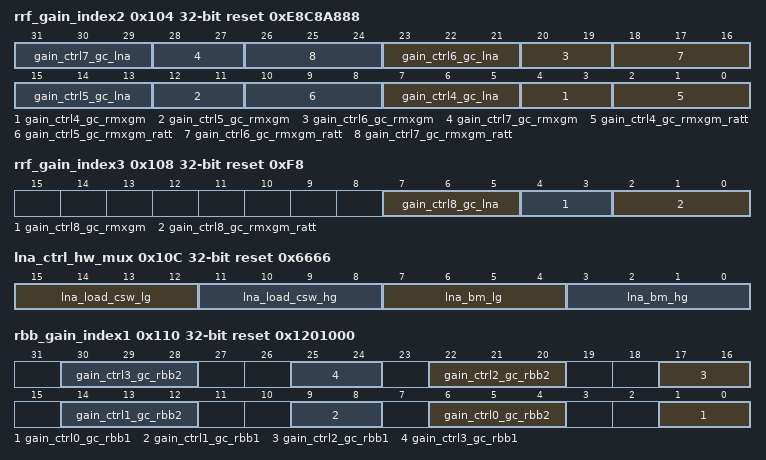
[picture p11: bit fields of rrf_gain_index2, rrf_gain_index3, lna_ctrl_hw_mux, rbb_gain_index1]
0x104 rrf_gain_index2 reset 0xE8C8A888
  [8n-25:8n-27] gain_ctrl{n}_gc_lna (n=4..7), [8n-28:8n-29] gain_ctrl{n}_gc_rmxgm (n=4..7), [8n-30:8n-32] gain_ctrl{n}_gc_rmxgm_ratt (n=4..7)
0x108 rrf_gain_index3 reset 0xF8
  [7:5] gain_ctrl8_gc_lna, [4:3] gain_ctrl8_gc_rmxgm, [2:0] gain_ctrl8_gc_rmxgm_ratt
0x10C lna_ctrl_hw_mux reset 0x6666
  [15:12] lna_load_csw_lg, [11:8] lna_load_csw_hg, [7:4] lna_bm_lg, [3:0] lna_bm_hg
0x110 rbb_gain_index1 reset 0x1201000
  [8n+6:8n+4] gain_ctrl{n}_gc_rbb2 (n=0..3), [8n+1:8n] gain_ctrl{n}_gc_rbb1 (n=0..3)
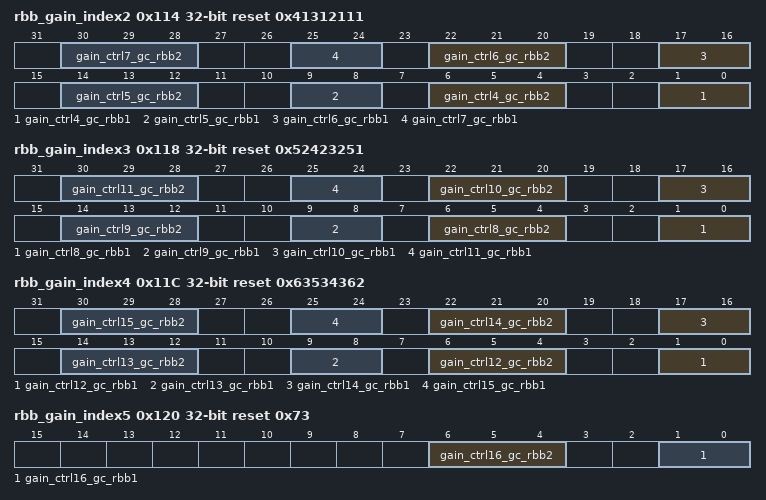
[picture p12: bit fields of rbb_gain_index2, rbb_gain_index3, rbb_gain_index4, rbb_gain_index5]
0x114 rbb_gain_index2 reset 0x41312111
  [8n-26:8n-28] gain_ctrl{n}_gc_rbb2 (n=4..7), [8n-31:8n-32] gain_ctrl{n}_gc_rbb1 (n=4..7)
0x118 rbb_gain_index3 reset 0x52423251
  [8n-58:8n-60] gain_ctrl{n}_gc_rbb2 (n=8..11), [8n-63:8n-64] gain_ctrl{n}_gc_rbb1 (n=8..11)
0x11C rbb_gain_index4 reset 0x63534362
  [8n-90:8n-92] gain_ctrl{n}_gc_rbb2 (n=12..15), [8n-95:8n-96] gain_ctrl{n}_gc_rbb1 (n=12..15)
0x120 rbb_gain_index5 reset 0x73
  [6:4] gain_ctrl16_gc_rbb2, [1:0] gain_ctrl16_gc_rbb1
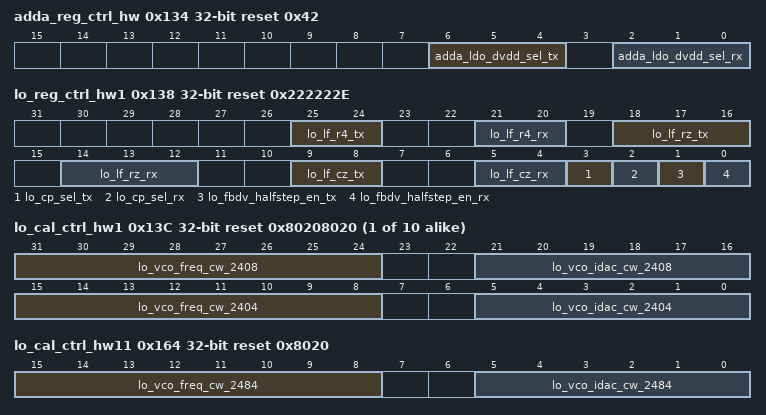
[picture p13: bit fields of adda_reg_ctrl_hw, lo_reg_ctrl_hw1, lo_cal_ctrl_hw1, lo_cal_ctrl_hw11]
0x134 adda_reg_ctrl_hw reset 0x42
  [6:4] adda_ldo_dvdd_sel_tx, [2:0] adda_ldo_dvdd_sel_rx
0x138 lo_reg_ctrl_hw1 reset 0x222222E
  [25:24] lo_lf_r4_tx, [21:20] lo_lf_r4_rx, [18:16] lo_lf_rz_tx, [14:12] lo_lf_rz_rx, [9:8] lo_lf_cz_tx, [5:4] lo_lf_cz_rx, [3] lo_cp_sel_tx, [2] lo_cp_sel_rx, [1] lo_fbdv_halfstep_en_tx, [0] lo_fbdv_halfstep_en_rx
{0x138+4i} lo_cal_ctrl_hw{i} reset 0x80208020 (i=1..10)
  [31:24] lo_vco_freq_cw_{8i+2400}, [21:16] lo_vco_idac_cw_{8i+2400}, [15:8] lo_vco_freq_cw_{8i+2396}, [5:0] lo_vco_idac_cw_{8i+2396}
0x164 lo_cal_ctrl_hw11 reset 0x8020
  [15:8] lo_vco_freq_cw_2484, [5:0] lo_vco_idac_cw_2484
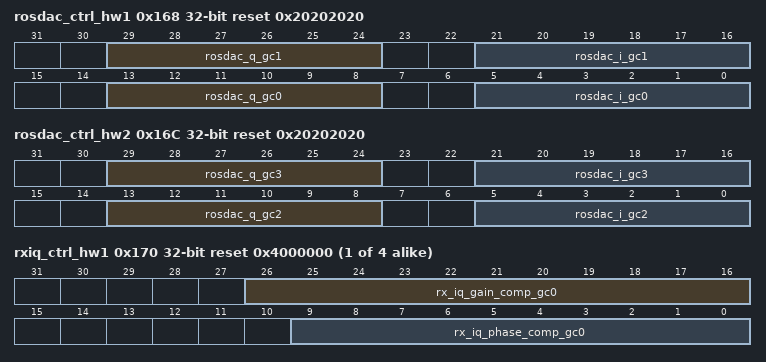
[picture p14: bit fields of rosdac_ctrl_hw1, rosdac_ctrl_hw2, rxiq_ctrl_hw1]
0x168 rosdac_ctrl_hw1 reset 0x20202020
  [29:24] rosdac_q_gc1, [21:16] rosdac_i_gc1, [13:8] rosdac_q_gc0, [5:0] rosdac_i_gc0
0x16C rosdac_ctrl_hw2 reset 0x20202020
  [29:24] rosdac_q_gc3, [21:16] rosdac_i_gc3, [13:8] rosdac_q_gc2, [5:0] rosdac_i_gc2
{0x16C+4i} rxiq_ctrl_hw{i} reset 0x4000000 (i=1..4)
  [26:16] rx_iq_gain_comp_gc{i-1}, [9:0] rx_iq_phase_comp_gc{i-1}
{0x17C+4i} tosdac_ctrl_hw{i} reset not defined (i=1..4)
{0x190+4i} tx_iq_gain_hw{i} reset not defined (i=0..7)
